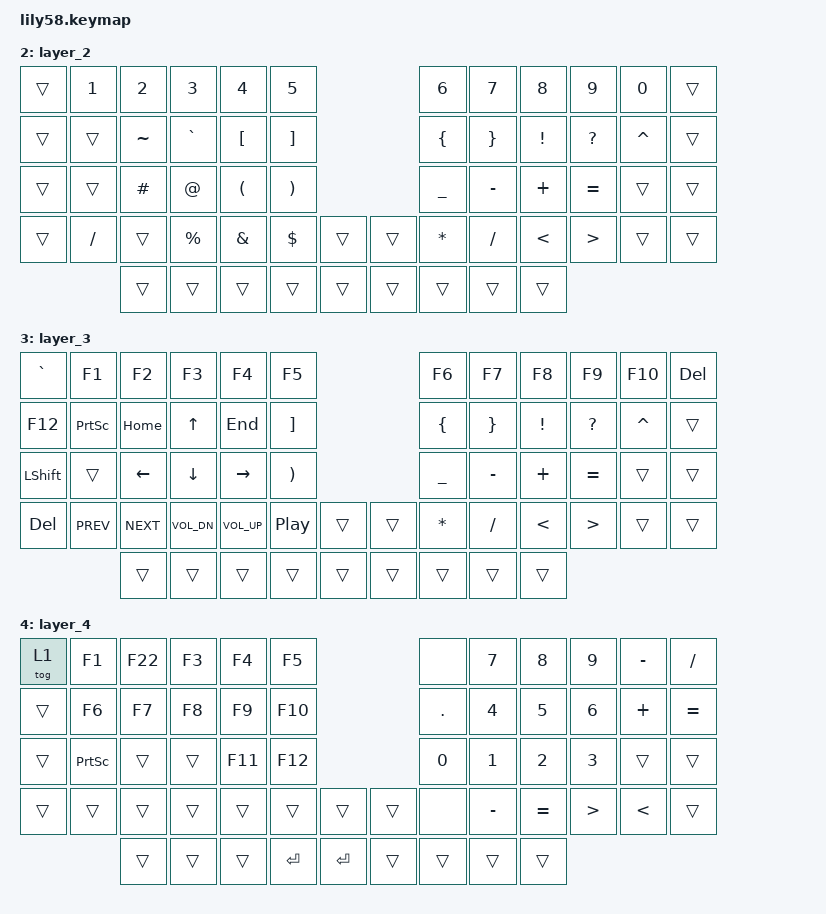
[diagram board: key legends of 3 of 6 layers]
/*
 * Copyright (c) 2020 The ZMK Contributors
 *
 * SPDX-License-Identifier: MIT
 */

#include <behaviors.dtsi>
#include <dt-bindings/zmk/keys.h>
#include <dt-bindings/zmk/bt.h>
#include <dt-bindings/zmk/ext_power.h>

/ {
    behaviors {
        mt: mod_tap {
            compatible = "zmk,behavior-hold-tap";
            #binding-cells = <2>;
            flavor = "balanced";
            tapping-term-ms = <200>;
            bindings = <&kp>, <&kp>;
            display-name = "Mod-Tap";  
        };
        lt: layer_tap {
            compatible = "zmk,behavior-hold-tap";
            #binding-cells = <2>;
            flavor = "balanced";
            tapping-term-ms = <200>;
            bindings = <&mo>, <&kp>;
            display-name = "Layer-Tap";
        };
        
        // UNITY MACROS //
        ma_unity0: ma_unity0 {
            compatible = "zmk,behavior-macro";
            #binding-cells = <0>;
            label = "SerializeField";
            bindings = < 
                &kp LEFT_BRACKET &kp LS(S) &kp E &kp R &kp I &kp A &kp L &kp I &kp Z &kp E &kp LS(F) &kp I &kp E &kp L &kp D &kp RIGHT_BRACKET
            >;
        };
        ma_unity1: ma_unity1 {
            compatible = "zmk,behavior-macro";
            #binding-cells = <0>;
            label = "GetComponent";
            bindings = < 
                &kp LS(G) &kp E &kp T &kp LS(C) &kp O &kp M &kp P &kp O &kp N &kp E &kp N &kp T
            >;
        };
        ma_unity2: ma_unity2 {
            compatible = "zmk,behavior-macro";
            #binding-cells = <0>;
            label = "GetComponentInChildren";
            bindings = < 
                &kp LS(G) &kp E &kp T &kp LS(C) &kp O &kp M &kp P &kp O &kp N &kp E &kp N &kp T &kp LS(I) &kp N &kp LS(C) &kp H &kp I &kp L &kp D &kp R &kp E &kp N
            >;
        };
        ma_unity3: ma_unity3 {
            compatible = "zmk,behavior-macro";
            #binding-cells = <0>;
            label = "GetComponentInParent";
            bindings = < 
                &kp LS(G) &kp E &kp T &kp LS(C) &kp O &kp M &kp P &kp O &kp N &kp E &kp N &kp T &kp LS(I) &kp N &kp LS(P) &kp A &kp R &kp E &kp N &kp T
            >;
        };
        ma_unity4: ma_unity4 {
            compatible = "zmk,behavior-macro";
            #binding-cells = <0>;
            label = "Debug.Log";
            bindings = < 
                &kp LS(D) &kp E &kp B &kp U &kp G &kp DOT
                &kp LS(L) &kp O &kp G
                &kp LPAR &kp DOLLAR &kp DOUBLE_QUOTES &kp DOUBLE_QUOTES &kp RPAR &kp SEMI
                &kp LEFT &kp LEFT &kp LEFT
            >;
        };
                ma_unity5: ma_unity5 {
            compatible = "zmk,behavior-macro";
            #binding-cells = <0>;
            label = "Debug.LogWarning";
            bindings = < 
                &kp LS(D) &kp E &kp B &kp U &kp G &kp DOT
                &kp LS(L) &kp O &kp G &kp LS(W) &kp A &kp R &kp N &kp I &kp N &kp G
                &kp LPAR &kp DOLLAR &kp DOUBLE_QUOTES &kp DOUBLE_QUOTES &kp RPAR &kp SEMI
                &kp LEFT &kp LEFT &kp LEFT
            >;
        };
                ma_unity6: ma_unity6 {
            compatible = "zmk,behavior-macro";
            #binding-cells = <0>;
            label = "Debug.LogError";
            bindings = < 
                &kp LS(D) &kp E &kp B &kp U &kp G &kp DOT
                &kp LS(L) &kp O &kp G &kp LS(E) &kp R &kp R &kp O &kp R
                &kp LPAR &kp DOLLAR &kp DOUBLE_QUOTES &kp DOUBLE_QUOTES &kp RPAR &kp SEMI
                &kp LEFT &kp LEFT &kp LEFT
            >;
        };
    };
};


/ {
  keymap {
    compatible = "zmk,keymap";

    layer_0 { // base
      bindings = <
        &kp ESC   &kp N1 &kp N2   &kp N3   &kp N4        &kp N5                              &kp N6 &kp N7        &kp N8     &kp N9  &kp N0   &kp BSPC
        &kp TAB   &kp Q  &kp W    &kp E    &kp R         &kp T                               &kp Y  &kp U         &kp I      &kp O   &kp P    &kp BSLH
        &kp LSHFT &kp A  &kp S    &lt 2 D  &mt LSHIFT F  &kp G                               &kp H  &mt LSHIFT J  &lt 2 K    &kp L   &kp SEMI &kp SQT
        &kp LCTRL &kp Z  &kp X    &kp C    &kp V         &kp B      &lt 4 DEL   &lt 4 BSPC   &kp N  &kp M         &kp COMMA  &kp DOT &kp FSLH &kp ENTER
                                  &kp LGUI &mo 3         &kp LALT   &kp SPACE   &kp SPACE    &mo 5  &mo 3         &kp DEL
      >;
    };

    layer_1 { // non-homerow mods base
      bindings = <
        &trans  &trans  &trans  &trans  &trans  &trans                    &trans  &trans  &trans  &trans  &trans  &trans
        &trans  &trans  &trans  &trans  &trans  &trans                    &trans  &trans  &trans  &trans  &trans  &trans
        &trans  &trans  &trans  &kp D   &kp F   &trans                    &trans  &kp J   &kp K   &trans  &trans  &trans
        &trans  &trans  &trans  &trans  &trans  &trans   &trans  &trans   &trans  &trans  &trans  &trans  &trans  &trans
                                &trans  &trans  &trans   &trans  &trans   &trans  &trans  &trans 
      >;
    };

    layer_2 { // homerow mods style
      bindings = <
        &trans   &kp N1    &kp N2    &kp N3       &kp N4         &kp N5                        &kp N6          &kp N7     &kp N8           &kp N9        &kp N0    &trans
        &trans   &trans    &kp TILDE &kp GRAVE    &kp LBKT       &kp RBKT                      &kp LBRC        &kp RBRC   &kp EXCLAMATION  &kp QUESTION  &kp CARET &trans
        &trans   &trans    &kp HASH  &kp AT       &kp LPAR       &kp RPAR                      &kp UNDERSCORE  &kp MINUS  &kp PLUS         &kp EQUAL     &trans    &trans
        &trans   &kp FSLH  &trans    &kp PERCENT  &kp AMPERSAND  &kp DOLLAR  &trans   &trans   &kp ASTERISK    &kp SLASH  &kp LT           &kp GT        &trans    &trans
                           &trans    &trans       &trans         &trans      &trans   &trans   &trans          &trans     &trans
      >;
    };

    layer_3 { // thumb clusters / navigation style
      bindings = <
        &kp GRAVE   &kp F1     &kp F2     &kp F3       &kp F4        &kp F5                       &kp F6         &kp F7     &kp F8           &kp F9        &kp F10     &kp DEL
        &kp F12     &kp PSCRN  &kp HOME   &kp UP       &kp END       &kp RBKT                     &kp LBRC       &kp RBRC   &kp EXCLAMATION  &kp QUESTION  &kp CARET   &trans
        &kp LSHFT   &trans     &kp LEFT   &kp DOWN     &kp RIGHT     &kp RPAR                     &kp UNDERSCORE &kp MINUS  &kp PLUS         &kp EQUAL     &trans      &trans
        &kp DEL     &kp C_PREV &kp C_NEXT &kp C_VOL_DN &kp C_VOL_UP  &kp C_PP    &trans   &trans  &kp ASTERISK   &kp SLASH  &kp LT           &kp GT        &trans      &trans
                               &trans     &trans       &trans        &trans      &trans   &trans  &trans         &trans     &trans
      >;
    };

    layer_4 { // functions and numbers
      bindings = <
        &tog 1   &kp F1    &kp F22    &kp F3       &kp F4    &kp F5                            &none    &kp N7      &kp N8     &kp N9  &kp MINUS &kp FSLH
        &trans   &kp F6    &kp F7     &kp F8       &kp F9    &kp F10                           &kp DOT  &kp N4      &kp N5     &kp N6  &kp PLUS  &kp EQUAL
        &trans   &kp PSCRN &trans     &trans       &kp F11   &kp F12                           &kp N0   &kp N1      &kp N2     &kp N3  &trans    &trans
        &trans   &trans    &trans     &trans       &trans    &trans    &trans     &trans       &none    &kp MINUS   &kp EQUAL  &kp GT  &kp LT    &trans
                                      &trans       &trans    &trans    &kp ENTER  &kp ENTER    &trans   &trans      &trans     &trans
      >;
    };

    layer_5{ // unity macros
      bindings = <
        &bt BT_CLR_ALL &trans &trans &trans &trans &trans                   &trans     &trans     &trans     &trans &trans &trans
        &trans &trans &trans &trans &trans &trans                   &ma_unity0 &trans     &trans     &trans &trans &trans
        &trans &trans &trans &trans &trans &trans                   &ma_unity1 &ma_unity2 &ma_unity3 &trans &trans &trans
        &trans &trans &trans &trans &trans &trans   &trans &trans   &ma_unity4 &ma_unity5 &ma_unity6 &trans &trans &trans
                             &trans &trans &trans   &trans &trans   &trans     &trans     &trans 
      >;

    };

  };
}; 

